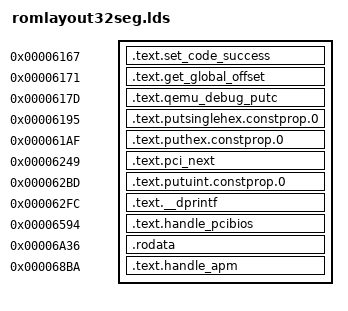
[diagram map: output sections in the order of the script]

/* DO NOT EDIT!  This is an autogenerated file.  See scripts/layoutrom.py. */
OUTPUT_FORMAT("elf32-i386")
OUTPUT_ARCH("i386")
SECTIONS
{
DebugOutputPort = 0x5f74 ;
MaxPCIBus = 0x54cc ;
entry_pcibios32 = 0xd1c9 ;
PirAddr = 0x54c8 ;
entry_apm16 = 0xd156 ;
entry_apm32 = 0xd197 ;
acpi_pm1a_cnt = 0x54c4 ;
.text.set_code_success 0x6167 : { *(.text.set_code_success) }
.text.get_global_offset 0x6171 : { *(.text.get_global_offset) }
.text.qemu_debug_putc 0x617d : { *(.text.qemu_debug_putc) }
.text.putsinglehex.constprop.0 0x6195 : { *(.text.putsinglehex.constprop.0) }
.text.puthex.constprop.0 0x61af : { *(.text.puthex.constprop.0) }
.text.pci_next 0x6249 : { *(.text.pci_next) }
.text.putuint.constprop.0 0x62bd : { *(.text.putuint.constprop.0) }
.text.__dprintf 0x62fc : { *(.text.__dprintf) }
.text.handle_pcibios 0x6594 : { *(.text.handle_pcibios) }
.rodata 0x6a36 : { *(.rodata) }
.text.handle_apm 0x68ba : { *(.text.handle_apm) }


        /* Discard regular data sections to force a link error if
         * code attempts to access data not marked with VAR16 (or other
         * appropriate macro)
         */
        /DISCARD/ : {
                *(.text*) *(.data*) *(.bss*) *(.rodata*)
                *(COMMON) *(.discard*) *(.eh_frame) *(.note*)
                }
}
